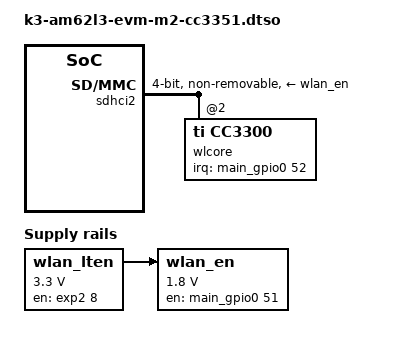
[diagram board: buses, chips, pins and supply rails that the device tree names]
// SPDX-License-Identifier: GPL-2.0-or-later OR MIT
/**
 * DT Overlay for M.2-CC3351 board to connect to the M.2 connector on AM62L-EVM.
 *
 * Product page for board: https://www.ti.com/tool/M2-CC3351
 * CC3351 Datasheet: https://www.ti.com/lit/ds/symlink/cc3351.pdf
 *
 * Copyright (C) 2025 Texas Instruments Incorporated - http://www.ti.com/
 */

/dts-v1/;
/plugin/;

#include <dt-bindings/gpio/gpio.h>
#include <dt-bindings/interrupt-controller/irq.h>
#include "k3-pinctrl.h"

&{/} {
	wlan_lten: regulator-30 {
		compatible = "regulator-fixed";
		regulator-name = "wlan_lten";
		regulator-min-microvolt = <3300000>;
		regulator-max-microvolt = <3300000>;
		gpios = <&exp2 8 GPIO_ACTIVE_HIGH>;
		enable-active-high;
	};

	wlan_en: regulator-31 {
		compatible = "regulator-fixed";
		regulator-name = "wlan_en";
		regulator-min-microvolt = <1800000>;
		regulator-max-microvolt = <1800000>;
		vin-supply = <&wlan_lten>;
		enable-active-high;
		gpios = <&main_gpio0 51 GPIO_ACTIVE_HIGH>;
		pinctrl-names = "default";
		pinctrl-0 = <&wlan_en_pins_default>;
	};
};

&pmx0 {
	main_mmc2_pins_default: main-mmc2-default-pins {
		pinctrl-single,pins = <
			AM62LX_IOPAD(0x010c, PIN_INPUT, 0) /* (U23) MMC2_CMD */
			AM62LX_IOPAD(0x0104, PIN_OUTPUT, 0) /* (R23) MMC2_CLK */
			AM62LX_IOPAD(0x0108, PIN_INPUT, 0) /* () MMC2_CLKLB */
			AM62LX_IOPAD(0x0100, PIN_INPUT, 0) /* (U22) MMC2_DAT0 */
			AM62LX_IOPAD(0x00fc, PIN_INPUT, 0) /* (T22) MMC2_DAT1 */
			AM62LX_IOPAD(0x00f8, PIN_INPUT, 0) /* (T23) MMC2_DAT2 */
			AM62LX_IOPAD(0x00f4, PIN_INPUT, 0) /* (R22) MMC2_DAT3 */
		>;
	};

	wlan_en_pins_default: wlan-en-pins-default {
		pinctrl-single,pins = <
			AM62LX_IOPAD(0x0110, PIN_OUTPUT, 7) /* (T20) MMC2_SDCD.GPIO0_51 */
		>;
	};

	main_wlirq_pins_default: main-wlirq-pins-default {
		pinctrl-single,pins = <
			AM62LX_IOPAD(0x0114, PIN_INPUT, 7) /* (T21) MMC2_SDWP.GPIO0_52 */
		>;
	};
};

&sdhci2 {
	bootph-all;
	vmmc-supply = <&wlan_en>;
	pinctrl-names = "default";
	pinctrl-0 = <&main_mmc2_pins_default>;
	bus-width = <4>;
	non-removable;
	ti,fails-without-test-cd;
	cap-power-off-card;
	keep-power-in-suspend;
	ti,driver-strength-ohm = <50>;
	#address-cells = <1>;
	#size-cells = <0>;
	status = "okay";

	wlcore: wlcore@2 {
		compatible = "ti,cc3300";
		reg = <2>;
		pinctrl-names = "default";
		pinctrl-0 = <&main_wlirq_pins_default>;
		interrupt-parent = <&main_gpio0>;
		interrupts = <52 IRQ_TYPE_EDGE_FALLING>;
	};
};
